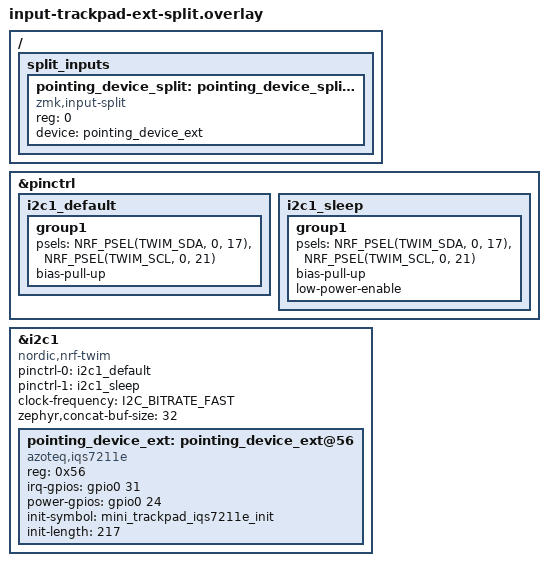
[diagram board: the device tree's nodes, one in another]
/*
 * peripheral 側の拡張FPC(extender)トラックパッド — split エクスポート版。
 *
 * 既存の `input-trackpad-ext` は listener 同梱の central 専用。こちらは peripheral 側に
 * 拡張パッドを載せる場合用で、listener を持たず `zmk,input-split` で central へ転送する
 * （central は既存の `input-split-listener` で受ける）。
 *
 * 配線は公式 extender と同一（input-trackpad-ext と揃える）:
 *   SDA=P0.17  SCL=P0.21  RDY(irq)=P0.31  POW=P0.24   ／ i2c1(TWIM1)
 * ⚠ POW=P0.24 は共有レール。FFC の電極面の向きを誤ると I2C ごとショートする（過去に実害あり）。
 *
 * reg スロット: このスニペットは reg=<0> を使う。つまり「拡張パッドが peripheral 側で唯一の
 * pointing デバイス」の構成専用（標準FFC が なし/エンコーダ の場合）。エンコーダは sensor 経路で
 * reg 枠を消費しないので、左=標準エンコーダ＋拡張パッド（PATTERN-MATRIX 行10/Group11）はここに該当。
 * 標準FFC にも pointing（ボール/パッド）が載る構成は reg=<1> 版が別途必要（バックログ）。
 *
 * パッド種別が自作(DIY)なら `input-trackpad-ext-diy` を後段に重ねて init を差し替える
 * （同じ &pointing_device_ext ラベルを上書きするので、この split 版にもそのまま効く）。
 */

&pinctrl {
    i2c1_default: i2c1_default {
        group1 {
            psels = <NRF_PSEL(TWIM_SDA, 0, 17)>,
                    <NRF_PSEL(TWIM_SCL, 0, 21)>;
            bias-pull-up;
        };
    };

    i2c1_sleep: i2c1_sleep {
        group1 {
            psels = <NRF_PSEL(TWIM_SDA, 0, 17)>,
                    <NRF_PSEL(TWIM_SCL, 0, 21)>;
            bias-pull-up;
            low-power-enable;
        };
    };
};

&i2c1 {
    status = "okay";
    compatible = "nordic,nrf-twim";
    pinctrl-0 = <&i2c1_default>;
    pinctrl-1 = <&i2c1_sleep>;
    pinctrl-names = "default", "sleep";
    clock-frequency = <I2C_BITRATE_FAST>;
    zephyr,concat-buf-size = <32>;

    pointing_device_ext: pointing_device_ext@56 {
        status = "okay";
        compatible = "azoteq,iqs7211e";
        reg = <0x56>;
        irq-gpios = <&gpio0 31 (GPIO_PULL_UP)>;
        power-gpios = <&gpio0 24 (GPIO_ACTIVE_HIGH | NRF_GPIO_DRIVE_H1)>;
        /* 公式 extender に載るのは MINI パッド。ドライバ既定 init は円形パッド向けで誤初期化になる。 */
        init-symbol = "mini_trackpad_iqs7211e_init";
        init-length = <217>;
    };
};

/ {
    split_inputs {
        #address-cells = <1>;
        #size-cells = <0>;

        pointing_device_split: pointing_device_split@0 {
            compatible = "zmk,input-split";
            reg = <0>;
            device = <&pointing_device_ext>;
        };
    };
};
